# ATA5795 device description
Architecture: AVR8; Family: megaAVR
Programming and debug interfaces: ISP, HVPP, debugWIRE
Registers are 8-bit, access not given, no defined reset value unless marked. A register's access mark holds for its fields unless they carry their own. Offsets are from the block's base; lines under a group give offsets from that group; [hi:lo] are bit positions; {n}, {i} and the like mark numbered series; 'fields as' and 'values as' point back to an identical list; <NAME> marks a mode.

## Ordering variants
standard: 1.9 to 3.6 V

## Memory
prog space: start 0x0000 size 0x2000, little endian
  0x0000 FLASH size 0x2000 flash, rw, executable, page 0x40
  0x1800 BOOT_SECTION_1 size 0x0800 flash, rw, executable, page 0x40
signatures space: start 0 size 3, little endian
  0 SIGNATURES size 3 signatures, ro
fuses space: start 0 size 0x0001, little endian
  0 FUSES size 0x0001 fuses, rw
lockbits space: start 0 size 0x0001, little endian
  0 LOCKBITS size 0x0001 lockbits, rw
data space: start 0x0000 size 0x0300, little endian
  0x0000 REGISTERS size 0x0020 regs
  0x0020 MAPPED_IO size 0x00e0 io
  0x0100 IRAM size 0x0200 ram
eeprom space: start 0x0000 size 0x0800, little endian
  0x0000 EEPROM size 0x0800 eeprom, rw, page 0x10
io space: start 0x00 size 0x40, little endian

## Peripheral instances (address, pins/pin function, parameters)
SPI at 0x00
AFE at 0x00
IRLED at 0x00
AES at 0x00
MOD at 0x00
VMON at 0x00
EXTERNAL_INTERRUPT at 0x00
EEPROM at 0x00
PORTB at 0x00
PORTD at 0x00
TIMER_COUNTER_0 at 0x00
TIMER_COUNTER_1 at 0x00
TIMER_COUNTER_2 at 0x00
TIMER_COUNTER_3 at 0x00
RTC_TIMER at 0x00
WDT at 0x00 — Watchdog Timer
PORTC at 0x00
CPU at 0x00
CRC at 0x00
FUSE at 0 in fuses
LOCKBIT at 0 in lockbits

## Interrupts
0 RESET — External Pin, Power-on Reset, Brown-out Reset, Watchdog Reset and Transponder Reset
1 TPINT — Transponder Mode Interrupt
2 INT0 — External Interrupt Request 0
3 PCINT0 — Pin Change Interrupt Request 0
4 PCINT1 — Pin Change Interrupt Request 1
5 VMINT — Voltage Monitor Interrupt
6 T0INT — Timer0 Interval Interrupt
7 T3CAPINT — Timer3 Capture Interrupt
8 T3COMINT — Timer3 Compare Match Interrupt
9 T3OVFINT — Timer3 Overflow Interrupt
10 T2COMINT — Timer2 Compare Match Interrupt
11 T2OVFINT — Timer2 Overflow Interrupt
12 T1INT — Timer1 Interval Interrupt
13 SPISTC — SPI Serial Transfer Complete
14 TMRXBINT — Timer Modulator SSI Receive Buffer Interrupt
15 TMTXBINT — Timer Modulator SSI Transmit Buffer Interrupt
16 TMTXCINT — Timer Modulator Transmit Complete Interrupt
17 AESINT — AES Interrupt
18 EXCMINT — External Input Clock Monitoring Interrupt
19 EXXMINT — External XTAL Oscillator Break Down Interrupt
20 RTCINT — Real Time Clock Interrupt
21 EEREADY — EEPROM Ready Interrupt
22 SPMREADY — Store Program Memory Ready

## Properties
SIGNATURES: JTAGID=0x9361, SIGNATURE0=0x1e, SIGNATURE1=0x93, SIGNATURE2=0x61
OCD: OCD_REVISION=1, OCD_DATAREG=0x31, PROGBASE=0x0000

## FUSE
Instances: FUSE 0 in fuses
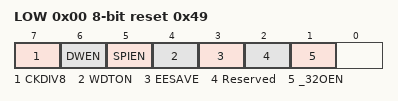
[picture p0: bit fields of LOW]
0x00 LOW reset 0x49
  [7] CKDIV8 — Divide clock by 8 internally
  [6] DWEN — DebugWIRE Enable
  [5] SPIEN — SPI Enable
  [4] WDTON — Enable Watchdog Timer
  [3] EESAVE — Preserve EEPROM through the Chip Erase cycle
  [2] Reserved — This fuse bit must be set.
  [1] _32OEN — Enables the 32 kHz oscillator.

## LOCKBIT
Instances: LOCKBIT 0 in lockbits
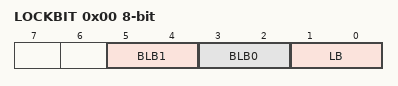
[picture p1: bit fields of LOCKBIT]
0x00 LOCKBIT
  [5:4] BLB1 — Boot Loader Protection Mode
    0=LPM and SPM prohibited in Boot Section; 1=LPM prohibited in Boot Section; 2=SPM prohibited in Boot Section; 3=No lock on SPM and LPM in Boot Section
  [3:2] BLB0 — Boot Loader Protection Mode
    0=LPM and SPM prohibited in Application Section; 1=LPM prohibited in Application Section; 2=SPM prohibited in Application Section; 3=No lock on SPM and LPM in Application Section
  [1:0] LB — Memory Lock
    0=Further programming and verification disabled; 2=Further programming disabled; 3=No memory lock features enabled

## SPI
Instances: SPI 0x00
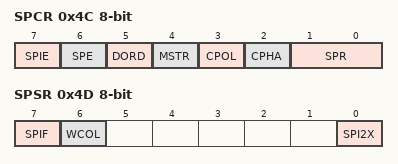
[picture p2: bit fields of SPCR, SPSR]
0x4C SPCR — SPI Control Register
  [7] SPIE — SPI Interrupt Enable
  [6] SPE — SPI Enable
  [5] DORD — Data Order
  [4] MSTR — Master/Slave Select
  [3] CPOL — Clock polarity
  [2] CPHA — Clock Phase
  [1:0] SPR — SPI Clock Rate Selects
    0=fosc/4; 1=fosc/16; 2=fosc/64; 3=fosc/128; 4=fosc/2; 5=fosc/8; 6=fosc/32; 7=fosc/64
0x4D SPSR — SPI Status Register
  [7] SPIF — SPI Interrupt Flag
  [6] WCOL — Write Collision Flag
  [0] SPI2X — Double SPI Speed Bit
0x4E SPDR — SPI Data Register
